AUTOSAR XML (schema 314)
package /ComponentType
  internal behavior Sa_DigHwTrqSENT_InternalBehavior: component=Sa_DigHwTrqSENT
    4 x timing event:
      DigHwTrqSENT_Init1_InitEvent: start-on-event=DigHwTrqSENT_Init1, period=0
      TMT_DigHwTrqSENT_Per1: start-on-event=DigHwTrqSENT_Per1, period=0.002
      TMT_DigHwTrqSENT_Per2: start-on-event=DigHwTrqSENT_Per2, period=0.004
      TMT_DigHwTrqSENT_Per3: start-on-event=DigHwTrqSENT_Per3, period=0.1
    4 x operation invoked event:
      OIT_DigHwTrqSENT_SCom_ClrTrqTrim_DigHwTrqSENT_SCom_ClrTrqTrim: start-on-event=DigHwTrqSENT_SCom_ClrTrqTrim, operation=DigHwTrqSENT_SCom.ClrTrqTrim
      OIT_DigHwTrqSENT_SCom_SetTrqTrim_DigHwTrqSENT_SCom_SetTrqTrim: start-on-event=DigHwTrqSENT_SCom_SetTrqTrim, operation=DigHwTrqSENT_SCom.SetTrqTrim
      OIT_DigHwTrqSENT_SCom_TrimData_DigHwTrqSENT_SCom_TrimData: start-on-event=DigHwTrqSENT_SCom_TrimData, operation=DigHwTrqSENT_SCom.TrimData
      OIT_DigHwTrqSENT_SCom_WriteData_DigHwTrqSENT_SCom_WriteData: start-on-event=DigHwTrqSENT_SCom_WriteData, operation=DigHwTrqSENT_SCom.WriteData
    per instance memory DigTrqTrim: type=DigHwTrqSENTTrim_DataType, type-definition=/DataType/DigHwTrqSENTTrim_DataType
    port-api-options:
      enable-take-address=false, indirect-api=false, port=DigHwTrqSENT_SCom
      enable-take-address=false, indirect-api=false, port=FaultInjection_SCom
      enable-take-address=false, indirect-api=false, port=HwTorque
      enable-take-address=false, indirect-api=false, port=MECCounter
      enable-take-address=false, indirect-api=false, port=NvM_DigHwTrqSENTTrim_Srv
      enable-take-address=false, indirect-api=false, port=NxtrDiagMgr
      enable-take-address=false, indirect-api=false, port=SrlComHwTrq
      enable-take-address=false, indirect-api=false, port=SrlComHwTrqValid
      enable-take-address=false, indirect-api=false, port=SysCHwTorque
      enable-take-address=false, indirect-api=false, port=T1
      enable-take-address=false, indirect-api=false, port=T2
    8 x runnable:
      DigHwTrqSENT_Init1
        data read access READ_MECCounter_Cnt_enum: data-element=MECCounter.Cnt_enum
        sync call SC_NvM_DigHwTrqSENTTrim_Srv_GetErrorStatus: operation=NvM_DigHwTrqSENTTrim_Srv.GetErrorStatus, timeout=0
        sync call SC_NxtrDiagMgr_SetNTCStatus: operation=NxtrDiagMgr.SetNTCStatus, timeout=0
      DigHwTrqSENT_Per1
        data read access READ_T1_HwNm_f32: data-element=T1.HwNm_f32
        data read access READ_T2_HwNm_f32: data-element=T2.HwNm_f32
        data write access WRITE_HwTorque_HwNm_f32: data-element=HwTorque.HwNm_f32
        data write access WRITE_SysCHwTorque_HwNm_f32: data-element=SysCHwTorque.HwNm_f32
        sync call SC_FaultInjection_SCom_FltInjection: operation=FaultInjection_SCom.FltInjection, timeout=0
      DigHwTrqSENT_Per2
        data write access WRITE_SrlComHwTrq_HwNm_f32: data-element=SrlComHwTrq.HwNm_f32
        data write access WRITE_SrlComHwTrqValid_Cnt_lgc: data-element=SrlComHwTrqValid.Cnt_lgc
        sync call SC_NxtrDiagMgr_GetNTCStatus: operation=NxtrDiagMgr.GetNTCStatus, timeout=0
        sync call SC_NxtrDiagMgr_SetNTCStatus: operation=NxtrDiagMgr.SetNTCStatus, timeout=0
      DigHwTrqSENT_Per3
      DigHwTrqSENT_SCom_ClrTrqTrim
        data receive point REC_MECCounter_Cnt_enum: data-element=MECCounter.Cnt_enum
        sync call SC_NvM_DigHwTrqSENTTrim_Srv_WriteBlock: operation=NvM_DigHwTrqSENTTrim_Srv.WriteBlock, timeout=0
        sync call SC_NxtrDiagMgr_SetNTCStatus: operation=NxtrDiagMgr.SetNTCStatus, timeout=0
      DigHwTrqSENT_SCom_SetTrqTrim
        data receive point REC_MECCounter_Cnt_enum: data-element=MECCounter.Cnt_enum
        data receive point REC_T1_HwNm_f32: data-element=T1.HwNm_f32
        data receive point REC_T2_HwNm_f32: data-element=T2.HwNm_f32
        sync call SC_NvM_DigHwTrqSENTTrim_Srv_WriteBlock: operation=NvM_DigHwTrqSENTTrim_Srv.WriteBlock, timeout=0
        sync call SC_NxtrDiagMgr_SetNTCStatus: operation=NxtrDiagMgr.SetNTCStatus, timeout=0
      DigHwTrqSENT_SCom_TrimData
      DigHwTrqSENT_SCom_WriteData
    service-needss:
      swc nv block needs DigHwTrqSENTTrim: n-data-sets=0, readonly=false, reliability=LOW, resistant-to-changed-sw=false, restore-at-start=false, write-only-once=false, writing-frequency=0, writing-priority=LOW, mirror-block=DigTrqTrim
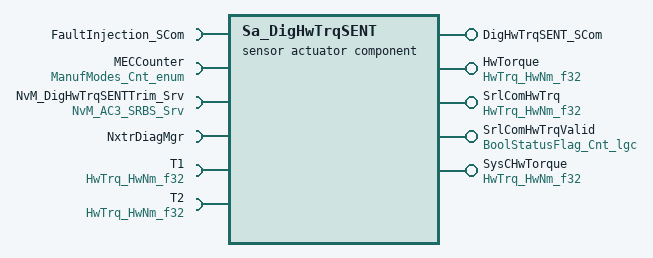
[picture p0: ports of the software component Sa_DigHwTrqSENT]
  sensor actuator software component type Sa_DigHwTrqSENT
    5 x provide port:
      DigHwTrqSENT_SCom: provided-interface=DigHwTrqSENT_SCom
        provided-com-specs:
          operation=ClrTrqTrim, queue-length=1
          operation=SetTrqTrim, queue-length=1
          operation=TrimData, queue-length=1
          operation=WriteData, queue-length=1
      HwTorque: unqueued-sender-com-spec{data-element=HwNm_f32, can-invalidate=false, init-value=D_ZERO_ULS_F32}, provided-interface=HwTrq_HwNm_f32
      SrlComHwTrq: unqueued-sender-com-spec{data-element=HwNm_f32, can-invalidate=false, init-value=D_ZERO_ULS_F32}, provided-interface=HwTrq_HwNm_f32
      SrlComHwTrqValid: unqueued-sender-com-spec{data-element=Cnt_lgc, can-invalidate=false, init-value=D_FALSE_CNT_LGC}, provided-interface=BoolStatusFlag_Cnt_lgc
      SysCHwTorque: unqueued-sender-com-spec{data-element=HwNm_f32, can-invalidate=false, init-value=D_ZERO_ULS_F32}, provided-interface=HwTrq_HwNm_f32
    6 x require port:
      FaultInjection_SCom: client-com-spec=FltInjection, required-interface=FaultInjection_SCom
      MECCounter: unqueued-receiver-com-spec{data-element=Cnt_enum, init-value=D_MANUFMODEINIT_CNT_ENUM}, required-interface=ManufModes_Cnt_enum
      NvM_DigHwTrqSENTTrim_Srv: required-com-specs=[EraseBlock, GetErrorStatus, InvalidateNvBlock, ReadBlock, SetRamBlockStatus, WriteBlock], required-interface=NvM_AC3_SRBS_Srv
      NxtrDiagMgr: required-com-specs=[GetNTCActive, GetNTCFailed, GetNTCStatus, SetNTCStatus], required-interface=NxtrDiagMgr
      T1: unqueued-receiver-com-spec{data-element=HwNm_f32, init-value=D_ZERO_ULS_F32}, required-interface=HwTrq_HwNm_f32
      T2: unqueued-receiver-com-spec{data-element=HwNm_f32, init-value=D_ZERO_ULS_F32}, required-interface=HwTrq_HwNm_f32
  swc implementation Sa_DigHwTrqSENT_Implementation: behavior=Sa_DigHwTrqSENT_InternalBehavior
    code-descriptors:
      code Code: type=SRC
